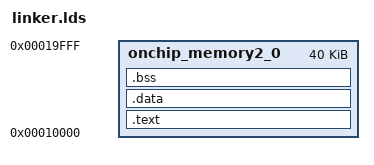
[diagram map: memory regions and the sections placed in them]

ENTRY(_start)

MEMORY
{
        onchip_memory2_0 : ORIGIN = 0x00010000, LENGTH = 40960
}

SECTIONS
{
        /**********************************************************************
         *                                                                    *
         **********************************************************************/
        .text :
        {
                _stext = .;
                *(.vectors)
                *(.startup)
                *(.text)
                *(.text.*)
                *(.rodata)
                *(.rodata.*)
                . = ALIGN(0x10);
                _etext = .;
        } > onchip_memory2_0
        /**********************************************************************
         *                                                                    *
         **********************************************************************/
        .data :
        {
                _sdata = .;
                *(.data)
                *(.data.*)
                *(.sdata)
                *(.sdata.*)
                . = ALIGN(0x10);
                _edata = .;
        } > onchip_memory2_0
        /**********************************************************************
         *                                                                    *
         **********************************************************************/
        _gp = ALIGN(4);
        /**********************************************************************
         *                                                                    *
         **********************************************************************/
        .bss ADDR(.data) + SIZEOF(.data) (NOLOAD) :
        {
                _sbss = .;
                *(.bss)
                *(.bss.*)
                *(COMMON)
                . = ALIGN(0x10);
                _ebss = .;
        } > onchip_memory2_0
        /**********************************************************************
         *                                                                    *
         **********************************************************************/
        .debug_info     0 : { *(.debug_info) }
        .debug_abbrev   0 : { *(.debug_abbrev) }
        .debug_aranges  0 : { *(.debug_aranges) }
        .debug_frame    0 : { *(.debug_frame) }
        .debug_line     0 : { *(.debug_line) }
        .debug_line_str 0 : { *(.debug_line_str) }
        .debug_loclists 0 : { *(.debug_loclists) }
        .debug_macro    0 : { *(.debug_macro) }
        .debug_names    0 : { *(.debug_names) }
        .debug_rnglists 0 : { *(.debug_rnglists) }
        .debug_str      0 : { *(.debug_str) }
        /**********************************************************************
         *                                                                    *
         **********************************************************************/
        /DISCARD/ :
        {
                *(*)
        }
}

